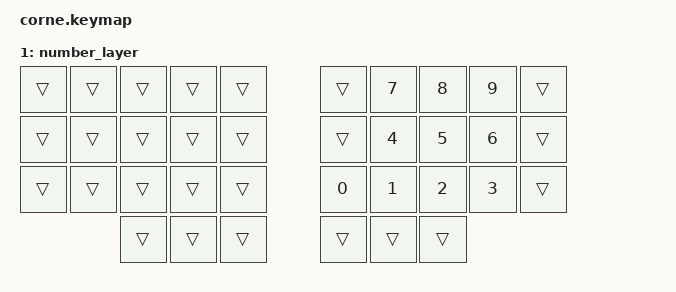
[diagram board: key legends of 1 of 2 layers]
#include <behaviors.dtsi>
#include <dt-bindings/zmk/keys.h>
#include <dt-bindings/zmk/bt.h>
#include <dt-bindings/zmk/outputs.h>


#include "keys/36.h"
#include "includes/behaviors.dtsi"

// layers
#define DEF     0
#define NUM     1
// #define SYM     2

// redefined keycodes
#define _LWIN_    &kp LEFT_WIN
#define _RALT_    &kp RIGHT_ALT
#define _SPC_     &kp SPACE
#define _RET_     &kp RETURN 

#define _MONUM_ &mo NUM
// #define _MOSYM_ &mo SYM

#define OUTTOG   &out OUT_TOG // toggle keyboard output bluetooth/usb
#define ___      &trans      //  transparent
#define _x_      &none

// Home row mods
#define HRML(k1, k2, k3, k4) &hml LSHFT k1 &hml LCTRL k2 &hml LALT  k3 &hml LGUI  k4
#define HRMR(k1, k2, k3, k4) &hmr RGUI  k1 &hmr RALT  k2 &hmr RCTRL k3 &hmr RSHFT k4

/ {
  chosen {
    zmk,matrix_transform = &five_column_transform;
  };
};

/ {
  keymap {
    compatible = "zmk,keymap";
    default_layer { 
      bindings = <
        // ╭─────────────────────────────────────────────────╮   ╭─────────────────────────────────────────────────╮
        // │    Q    │    W    │    E    │    R    │    T    │   │    Y    │    U    │    I    │    O    │    P    │
            &kp Q     &kp W     &kp E     &kp R     &kp T         &kp Y     &kp U     &kp I     &kp O     &kp P
        // ├─────────┼─────────┼─────────┼─────────┼─────────┤   ├─────────┼─────────┼─────────┼─────────┼─────────┤
        // │    A    │    S    │    D    │    F    │    G    │   │    H    │    J    │    K    │    L    │    '    │
            HRML(A,       S,        D,        F)    &kp G         &kp H     HRMR(J,       K,        L,       SQT)
        // ├─────────┼─────────┼─────────┼─────────┼─────────┤   ├─────────┼─────────┼─────────┼─────────┼─────────┤
        // │    Z    │    X    │    C    │    V    │    B    │   │    N    │    M    │   ,/;   │   ./:   │    /    │
            &kp Z     &kp X     &kp C     &kp V     &kp B         &kp N     &kp M     &cma_smi  &dot_cln  &kp FSLH
        // ╰─────────┼─────────┼─────────┼─────────┼─────────┤   ├─────────┼─────────┼─────────┼─────────┼─────────╯
                                  _LWIN_   _MONUM_    _SPC_         _RET_      _x_      _RALT_
        //                     ╰─────────────────────────────╯   ╰─────────────────────────────╯
      >;
    };

    number_layer { 
      bindings = <
        // ╭─────────────────────────────────────────────────╮   ╭─────────────────────────────────────────────────╮
        // │    _    │    _    │    _    │    _    │    _    │   │    _    │    7    │    8   │     9    │    _    │
               ___       ___       ___       ___       ___           ___       &kp 7    &kp 8     &kp 9      ___
        // ├─────────┼─────────┼─────────┼─────────┼─────────┤   ├─────────┼─────────┼─────────┼─────────┼─────────┤
        // │    _    │    _    │    _    │    _    │    _    │   │    _    │    4    │    5    │    6    │    _    │
               ___       ___       ___       ___       ___           ___       &kp 4    &kp 5     &kp 6      ___
        // ├─────────┼─────────┼─────────┼─────────┼─────────┤   ├─────────┼─────────┼─────────┼─────────┼─────────┤
        // │    _    │    _    │    _    │    _    │    _    │   │    0    │    1    │    2    │    3    │    _    │
               ___       ___       ___       ___       ___           &kp 0     &kp 1    &kp 2     &kp 3      ___
        // ╰─────────┼─────────┼─────────┼─────────┼─────────┤   ├─────────┼─────────┼─────────┼─────────┼─────────╯
                                   ___       ___       ___           ___       ___       ___ 
        //                     ╰─────────────────────────────╯   ╰─────────────────────────────╯
      >;
    };

  };
};

// vim:ft=cpp
